# RZN2H register map
Vendor: Renesas Electronics Corporation; Series: RZN; File version: 1.00.00
CPU: other r0p0, little endian, MPU, no FPU, VTOR, 4 interrupt priority bits, 624 interrupts
Registers are 32-bit, read-write, reset 0x0 unless marked. A register's access mark holds for its fields unless they carry their own. Offsets are from the block's base; [hi:lo] are bit positions; {n}, {i} and the like mark numbered series.

## HDSLS10 — HIPERFACE DSL for Safe Channel 1 Unit 0
Base 0x90201000
Same registers: HDSLS{n} {0x90161000+0x10000*n} (n=11..19), HDSLS110 0x902A1000, HDSLS111 0x902B1000, HDSLS112 0x90301000, HDSLS113 0x90311000, HDSLS114 0x90321000, HDSLS115 0x90331000
0x09 EDGES 8-bit ro — Edge Register
  [7:0] EDGES — Identification of edges in the cable signal
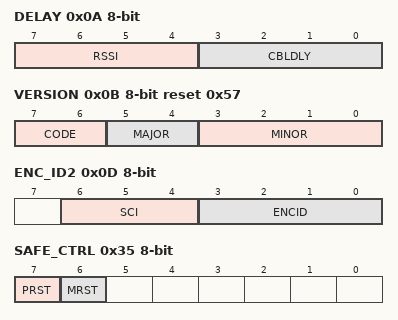
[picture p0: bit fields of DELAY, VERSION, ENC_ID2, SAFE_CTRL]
0x0A DELAY 8-bit ro — Run Time Delay Register
  [7:4] RSSI — Indication of the received signal strength
  [3:0] CBLDLY — 4-bit value for cable delay
0x0B VERSION 8-bit ro reset 0x57
  [7:6] CODE — Type of module
    1=DSL Master; other=Others (Reserved)
  [5:4] MAJOR — Major release number
  [3:0] MINOR — Minor release number
0x0D ENC_ID2 8-bit ro — Encoder ID 2 Register
  [6:4] SCI — Indication of special characters
  [3:0] ENCID — Encoder designation code bit 19 to bit 16
0x0E ENC_ID1 8-bit ro — Encoder ID 1 Register
  [7:0] ENCID — Encoder designation code, byte n
0x0F ENC_ID0 8-bit ro — Encoder ID 0 Register
  [7:0] ENCID — Encoder designation code, byte n
0x19 VPOS4 8-bit ro — Safe Position 4 Register
  [7:0] VPOS — Safe position, byte n
0x1A VPOS3 8-bit ro — Safe Position 3 Register
  [7:0] VPOS — Safe position, byte n
0x1B VPOS2 8-bit ro — Safe Position 2 Register
  [7:0] VPOS — Safe position, byte n
0x1C VPOS1 8-bit ro — Safe Position 1 Register
  [7:0] VPOS — Safe position, byte n
0x1D VPOS0 8-bit ro — Safe Position 0 Register
  [7:0] VPOS — Safe position, byte n
0x1E VPOSCRC_H 8-bit ro — Safe Position CRC High Byte Register
  [7:0] VPOSCRCH — CRC of the safe position, bit 15 to bit 8
0x1F VPOSCRC_L 8-bit ro — Safe Position CRC Low Byte Register
  [7:0] VPOSCRCL — CRC of the safe position, bit 7 to bit 0
0x35 SAFE_CTRL 8-bit — Safe System Control Register
  [7] PRST — Protocol reset
    0=Normal protocol action; 1=A forced reset of the protocol status will be initiated. If the bit is deleted, a restart of the connection is triggered.
  [6] MRST — Message reset
    0=Normal Parameters Channel action; 1=The Parameters Channel is reset. Current short and long messages are discarded.
0x36 SAFE_SUM 8-bit ro — Safety Status Summary Register
  [7:0] SSUM — Status summary bit
0x37 S_PC_DATA 8-bit ro — Parameter Channel Short Message Register
  [7:0] SPCDATA — "Short message" Parameter Channel data
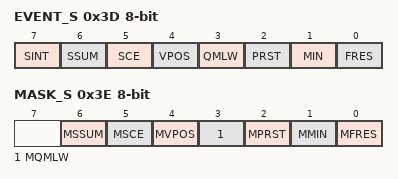
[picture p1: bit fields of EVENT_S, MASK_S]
0x3D EVENT_S 8-bit — Safe Event Register
  [7] SINT ro — Safe interrupt status
  [6] SSUM — Remote event monitoring
    0=All DSL Slave events are cleared; 1=The DSL Slave has signaled an event
  [5] SCE — Error on the Safe Channel
    0=Safe Channel data was correctly transmitted; 1=Data consistency error on the Safe Channel
  [4] VPOS — Safe position error
    0=The safe position is correct; 1=Sensor error
  [3] QMLW — Quality monitoring low-value warning
    0=Quality monitoring value, QM[3:0] in the MASTERQM register, greater than or equal to "14"; 1=Quality monitoring value below "14"
  [2] PRST — Protocol reset warning
    0=Normal protocol action; 1=The forced protocol reset was triggered
  [1] MIN — Message init
    0=No acknowledgment for the initialization received; 1=An acknowledgment was received from the Slave for the initialization of a message
  [0] FRES — Channel free for "short message"
    0=No "short message" can be sent; 1=A "short message" can be sent on the Parameters Channel
0x3E MASK_S 8-bit wo — Safe Event Mask Register
  [6] MSSUM — Mask for remote event monitoring
    0=DSL Slave events that are set in the SAFE_SUM register do not set the safety-related interrupt signal; 1=DSL Slave events that are set in the SAFE_SUM register sets the safety-related interrupt signal
  [5] MSCE — Mask for transmission errors on the Safe Channel
    0=A transmission error on the Safe Channel does not set the safety-related interrupt signal; 1=A transmission error on the Safe Channel sets the safety-related interrupt signal
  [4] MVPOS — Mask for safe position error
    0=An error in the safe position does not set the safety-related interrupt signal; 1=An error in the safe position sets the safety-related interrupt signal
  [3] MQMLW — Mask for low-quality monitoring value warning
    0=A low-quality monitoring value does not set the safety-related interrupt signal; 1=A low-quality monitoring value sets the safety-related interrupt signal
  [2] MPRST — Mask for protocol reset warning
    0=A protocol reset does not set the safety-related interrupt signal; 1=A protocol reset sets the safety-related interrupt signal
  [1] MMIN — Mask for message initialization confirmation
    0=The acknowledgment for the initialization of a DSL Slave message does not set the safety-related interrupt signal; 1=The acknowledgment for the initialization of a DSL Slave message sets the safety-related interrupt signal
  [0] MFRES — Mask for "channel free for "short message""
    0=If a "short message" can be sent on the Parameters Channel, the safety-related interrupt signal is not set; 1=If a "short message" can be sent on the Parameters Channel, the safety-related interrupt signal is set
0x3F DUMMY 8-bit ro reset not defined
  [7:0] DUMMY — Due to the transmission of the online-status, Online Status read transactions need less time for transmission. Therefore, dummy read transactions must be inserted to avoid unwanted extra transactions.
{0x40+i} ENC_ST{i} (i=0..7) 8-bit — Encoder Status {i} Register
  [7:0] ENCST — Encoder status, byte n
0x7C SRSSI 8-bit ro — Slave RSSI Register
  [2:0] SRSSI — Value of the Slave RSSI
0x7E MAIL 8-bit wo — Slave Mail Register
  [7:0] MAIL — Slave-Mail
0x7F PING 8-bit — Slave Ping Register
  [7:0] PING — Slave-Ping
